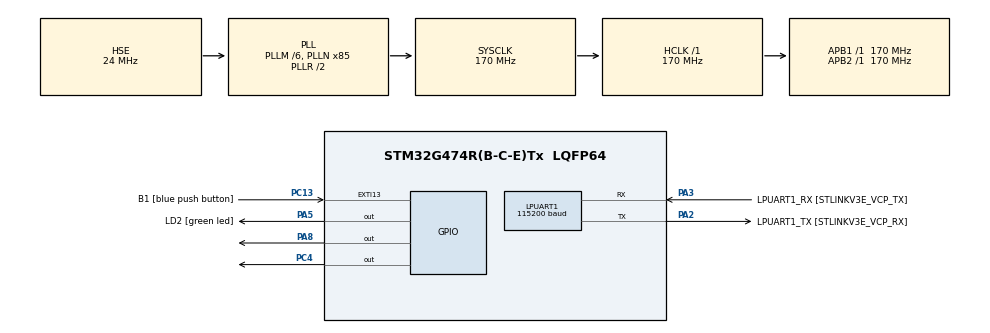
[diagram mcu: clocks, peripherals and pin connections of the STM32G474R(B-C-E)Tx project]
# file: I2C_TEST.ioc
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Mcu.Family=STM32G4
RCC.PLLSourceVirtual=RCC_PLLSOURCE_HSE
PC15-OSC32_OUT.Mode=LSE-External-Oscillator
RCC.CortexFreq_Value=170000000
PC13.Signal=GPXTI13
PA14.GPIO_Label=T_SWCLK
PC4.Signal=GPIO_Output
LPUART1.WordLength=UART_WORDLENGTH_8B
RCC.EXTERNAL_CLOCK_VALUE=12288000
PC13.GPIO_Label=B1 [blue push button]
PC14-OSC32_IN.Signal=RCC_OSC32_IN
RCC.SYSCLKSource=RCC_SYSCLKSOURCE_PLLCLK
ProjectManager.StackSize=0x400
PA13.Signal=SYS_JTMS-SWDIO
PA3.Mode=Asynchronous
ProjectManager.TargetToolchain=STM32CubeIDE
RCC.HCLKFreq_Value=170000000
RCC.APB2TimFreq_Value=170000000
RCC.USBFreq_Value=170000000
PC15-OSC32_OUT.Signal=RCC_OSC32_OUT
RCC.AHBFreq_Value=170000000
PF0-OSC_IN.Mode=HSE-External-Oscillator
NVIC.EXTI15_10_IRQn=true\:0\:0\:false\:false\:true\:true\:true
PA5.Signal=GPIO_Output
RCC.HSE_VALUE=24000000
board=NUCLEO-G474RE
RCC.VCOOutputFreq_Value=340000000
RCC.ADC12Freq_Value=170000000
RCC.RTCClockSelection=RCC_RTCCLKSOURCE_LSE
RCC.ADC345Freq_Value=170000000
RCC.APB2Freq_Value=170000000
PC14-OSC32_IN.Mode=LSE-External-Oscillator
PA14.Mode=Serial_Wire
VP_SYS_VS_DBSignals.Mode=DisableDeadBatterySignals
PA8.Signal=GPIO_Output
PA8.GPIO_ModeDefaultOutputPP=GPIO_MODE_OUTPUT_OD
PA13.Mode=Serial_Wire
Mcu.Name=STM32G474R(B-C-E)Tx
LPUART1.BaudRate=115200
PA2.Signal=LPUART1_TX
PA13.GPIO_Label=T_SWDIO
PB3.Signal=SYS_JTDO-SWO
RCC.SYSCLKFreq_VALUE=170000000
Mcu.Package=LQFP64
PA5.GPIO_Label=LD2 [green led]
PA2.GPIO_Label=LPUART1_TX [STLINKV3E_VCP_RX]
PA14.Signal=SYS_JTCK-SWCLK
ProjectManager.HeapSize=0x200
RCC.HSI_VALUE=16000000
PA8.GPIO_PuPd=GPIO_PULLUP
NVIC.PriorityGroup=NVIC_PRIORITYGROUP_4
RCC.PLLM=RCC_PLLM_DIV6
RCC.PLLN=85
RCC.APB1TimFreq_Value=170000000
PA2.Mode=Asynchronous
PF0-OSC_IN.Signal=RCC_OSC_IN
PF1-OSC_OUT.Mode=HSE-External-Oscillator
RCC.APB1Freq_Value=170000000
PF1-OSC_OUT.Signal=RCC_OSC_OUT
RCC.HSI48_VALUE=48000000
PA3.GPIO_Label=LPUART1_RX [STLINKV3E_VCP_TX]
PA3.Signal=LPUART1_RX
PB3.GPIO_Label=T_SWO

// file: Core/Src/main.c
/* USER CODE BEGIN Header */
/**
  ******************************************************************************
  * @file           : main.c
  * @brief          : Main program body
  ******************************************************************************
  * @attention
  *
  * <h2><center>&copy; Copyright (c) 2021 STMicroelectronics.
  * All rights reserved.</center></h2>
  *
  * This software component is licensed by ST under BSD 3-Clause license,
  * the "License"; You may not use this file except in compliance with the
  * License. You may obtain a copy of the License at:
  *                        opensource.org/licenses/BSD-3-Clause
  *
  ******************************************************************************
  */
/* USER CODE END Header */
#include "main.h"
#include "usart.h"
#include "gpio.h"

/* USER CODE BEGIN Includes */
#include "iic.h"
/* USER CODE END Includes */

void SystemClock_Config(void);

int main(void)
{

  /* MCU Configuration--------------------------------------------------------*/

  /* Reset of all peripherals, Initializes the Flash interface and the Systick. */
  HAL_Init();

  /* Configure the system clock */
  SystemClock_Config();

  /* Initialize all configured peripherals */
  MX_GPIO_Init();
  MX_LPUART1_UART_Init();

  /* Infinite loop */
  while (1)
  {

  }
}

void SystemClock_Config(void)
{
  RCC_OscInitTypeDef RCC_OscInitStruct = {0};
  RCC_ClkInitTypeDef RCC_ClkInitStruct = {0};
  RCC_PeriphCLKInitTypeDef PeriphClkInit = {0};

  /** Configure the main internal regulator output voltage
  */
  HAL_PWREx_ControlVoltageScaling(PWR_REGULATOR_VOLTAGE_SCALE1_BOOST);
  /** Initializes the RCC Oscillators according to the specified parameters
  * in the RCC_OscInitTypeDef structure.
  */
  RCC_OscInitStruct.OscillatorType = RCC_OSCILLATORTYPE_HSE;
  RCC_OscInitStruct.HSEState = RCC_HSE_ON;
  RCC_OscInitStruct.PLL.PLLState = RCC_PLL_ON;
  RCC_OscInitStruct.PLL.PLLSource = RCC_PLLSOURCE_HSE;
  RCC_OscInitStruct.PLL.PLLM = RCC_PLLM_DIV6;
  RCC_OscInitStruct.PLL.PLLN = 85;
  RCC_OscInitStruct.PLL.PLLP = RCC_PLLP_DIV2;
  RCC_OscInitStruct.PLL.PLLQ = RCC_PLLQ_DIV2;
  RCC_OscInitStruct.PLL.PLLR = RCC_PLLR_DIV2;
  if (HAL_RCC_OscConfig(&RCC_OscInitStruct) != HAL_OK)
  {
    Error_Handler();
  }
  /** Initializes the CPU, AHB and APB buses clocks
  */
  RCC_ClkInitStruct.ClockType = RCC_CLOCKTYPE_HCLK|RCC_CLOCKTYPE_SYSCLK
                              |RCC_CLOCKTYPE_PCLK1|RCC_CLOCKTYPE_PCLK2;
  RCC_ClkInitStruct.SYSCLKSource = RCC_SYSCLKSOURCE_PLLCLK;
  RCC_ClkInitStruct.AHBCLKDivider = RCC_SYSCLK_DIV1;
  RCC_ClkInitStruct.APB1CLKDivider = RCC_HCLK_DIV1;
  RCC_ClkInitStruct.APB2CLKDivider = RCC_HCLK_DIV1;

  if (HAL_RCC_ClockConfig(&RCC_ClkInitStruct, FLASH_LATENCY_4) != HAL_OK)
  {
    Error_Handler();
  }
  /** Initializes the peripherals clocks
  */
  PeriphClkInit.PeriphClockSelection = RCC_PERIPHCLK_LPUART1;
  PeriphClkInit.Lpuart1ClockSelection = RCC_LPUART1CLKSOURCE_PCLK1;
  if (HAL_RCCEx_PeriphCLKConfig(&PeriphClkInit) != HAL_OK)
  {
    Error_Handler();
  }
}

void Error_Handler(void)
{
  __disable_irq();
  while (1)
  {
  }
}

/************************ (C) COPYRIGHT STMicroelectronics *****END OF FILE****/
